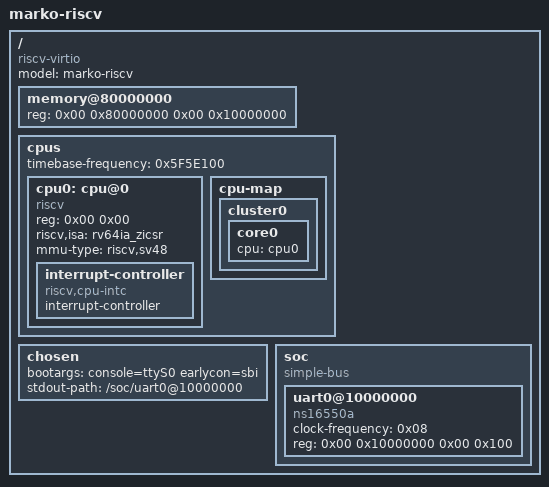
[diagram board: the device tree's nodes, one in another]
/dts-v1/;

/ {
    #address-cells = <0x02>;
    #size-cells = <0x02>;
    compatible = "riscv-virtio";
    model = "marko-riscv";

    memory@80000000 {
        device_type = "memory";
        reg = <0x00 0x80000000 0x00 0x10000000>;
    };

    cpus {
        #address-cells = <0x02>;
        #size-cells = <0x00>;
        timebase-frequency = <0x5F5E100>;

        cpu0: cpu@0 {
            device_type = "cpu";
            reg = <0x00 0x00>;
            status = "okay";
            compatible = "riscv";
            riscv,isa = "rv64ia_zicsr";
            mmu-type = "riscv,sv48";

            interrupt-controller {
                #interrupt-cells = <0x01>;
                interrupt-controller;
                compatible = "riscv,cpu-intc";
            };
        };

        cpu-map {
            cluster0 {
                core0 {
                    cpu = <&cpu0>;
                };
            };
        };
    };

    chosen {
        bootargs = "console=ttyS0 earlycon=sbi";
        stdout-path = "/soc/uart0@10000000";
    };

    soc {
        #address-cells = <0x02>;
        #size-cells = <0x02>;
        compatible = "simple-bus";

        uart0@10000000 {
            clock-frequency = <0x08>;
            reg = <0x00 0x10000000 0x00 0x100>;
            compatible = "ns16550a";
        };
    };
};
